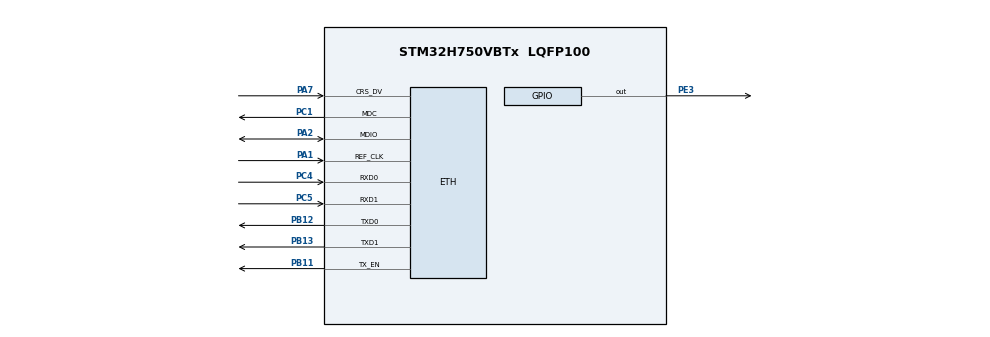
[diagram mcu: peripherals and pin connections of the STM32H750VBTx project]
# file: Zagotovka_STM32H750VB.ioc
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CORTEX_M7.AccessPermission-Cortex_Memory_Protection_Unit_Region0_Settings=MPU_REGION_FULL_ACCESS
CORTEX_M7.AccessPermission-Cortex_Memory_Protection_Unit_Region1_Settings=MPU_REGION_FULL_ACCESS
CORTEX_M7.AccessPermission-Cortex_Memory_Protection_Unit_Region2_Settings=MPU_REGION_FULL_ACCESS
CORTEX_M7.AccessPermission-Cortex_Memory_Protection_Unit_Region3_Settings=MPU_REGION_FULL_ACCESS
CORTEX_M7.BaseAddress-Cortex_Memory_Protection_Unit_Region0_Settings=0x30000000
CORTEX_M7.BaseAddress-Cortex_Memory_Protection_Unit_Region1_Settings=0x30000000
CORTEX_M7.BaseAddress-Cortex_Memory_Protection_Unit_Region2_Settings=0x90000000
CORTEX_M7.BaseAddress-Cortex_Memory_Protection_Unit_Region3_Settings=0x90000000
CORTEX_M7.CPU_DCache=Enabled
CORTEX_M7.CPU_ICache=Enabled
CORTEX_M7.DisableExec-Cortex_Memory_Protection_Unit_Region0_Settings=MPU_INSTRUCTION_ACCESS_DISABLE
CORTEX_M7.DisableExec-Cortex_Memory_Protection_Unit_Region1_Settings=MPU_INSTRUCTION_ACCESS_DISABLE
CORTEX_M7.DisableExec-Cortex_Memory_Protection_Unit_Region2_Settings=MPU_INSTRUCTION_ACCESS_DISABLE
CORTEX_M7.Enable-Cortex_Memory_Protection_Unit_Region0_Settings=MPU_REGION_ENABLE
CORTEX_M7.Enable-Cortex_Memory_Protection_Unit_Region1_Settings=MPU_REGION_ENABLE
CORTEX_M7.Enable-Cortex_Memory_Protection_Unit_Region2_Settings=MPU_REGION_ENABLE
CORTEX_M7.Enable-Cortex_Memory_Protection_Unit_Region3_Settings=MPU_REGION_ENABLE
CORTEX_M7.IsBufferable-Cortex_Memory_Protection_Unit_Region1_Settings=MPU_ACCESS_BUFFERABLE
CORTEX_M7.IsBufferable-Cortex_Memory_Protection_Unit_Region2_Settings=MPU_ACCESS_BUFFERABLE
CORTEX_M7.IsBufferable-Cortex_Memory_Protection_Unit_Region3_Settings=MPU_ACCESS_BUFFERABLE
CORTEX_M7.IsCacheable-Cortex_Memory_Protection_Unit_Region2_Settings=MPU_ACCESS_CACHEABLE
CORTEX_M7.IsCacheable-Cortex_Memory_Protection_Unit_Region3_Settings=MPU_ACCESS_CACHEABLE
CORTEX_M7.IsShareable-Cortex_Memory_Protection_Unit_Region1_Settings=MPU_ACCESS_SHAREABLE
CORTEX_M7.MPU_Control=MPU_PRIVILEGED_DEFAULT
CORTEX_M7.Size-Cortex_Memory_Protection_Unit_Region0_Settings=MPU_REGION_SIZE_32KB
CORTEX_M7.Size-Cortex_Memory_Protection_Unit_Region1_Settings=MPU_REGION_SIZE_256B
CORTEX_M7.Size-Cortex_Memory_Protection_Unit_Region2_Settings=MPU_REGION_SIZE_8MB
CORTEX_M7.Size-Cortex_Memory_Protection_Unit_Region3_Settings=MPU_REGION_SIZE_1MB
CORTEX_M7.TypeExtField-Cortex_Memory_Protection_Unit_Region0_Settings=MPU_TEX_LEVEL1
ETH.MediaInterface=HAL_ETH_RMII_MODE
FREERTOS.Tasks01=defaultTask,0,5000,StartDefaultTask,Default,NULL,Static,defaultTaskBuffer,defaultTaskControlBlock;myTask02,1,128,StartTask02,Default,NULL,Static,myTask02Buffer,myTask02ControlBlock
FREERTOS.configTOTAL_HEAP_SIZE=50000
FREERTOS.configUSE_NEWLIB_REENTRANT=1
LWIP.BSP.number=1
LWIP.DEFAULT_THREAD_STACKSIZE=2000
LWIP.GATEWAY_ADDRESS=195.168.018.001
LWIP.IP_ADDRESS=192.168.018.115
LWIP.LWIP_DHCP=0
LWIP.LWIP_HTTPD=1
LWIP.LWIP_HTTPD_CGI=1
LWIP.LWIP_HTTPD_DYNAMIC_HEADERS=0
LWIP.LWIP_HTTPD_MAX_TAG_INSERT_LEN=1000
LWIP.LWIP_HTTPD_SSI=1
LWIP.LWIP_HTTPD_SSI_INCLUDE_TAG=0
LWIP.LWIP_HTTPD_SSI_MULTIPART=1
LWIP.LWIP_HTTPD_SUPPORT_POST=1
LWIP.LWIP_RAM_HEAP_POINTER=0x30004000
LWIP.MEMP_NUM_TCP_PCB=6
LWIP.MEMP_NUM_UDP_PCB=6
LWIP.MEM_SIZE=10*1024
LWIP.NETMASK_ADDRESS=255.255.255.000
LWIP.PBUF_POOL_BUFSIZE=592
LWIP.TCPIP_THREAD_STACKSIZE=3072
LWIP.Version=v2.1.2_Cube
LWIP0.BSP.STBoard=false
LWIP0.BSP.api=BSP_COMPONENT_DRIVER
LWIP0.BSP.component=LAN8742
LWIP0.BSP.instance=LAN8742
LWIP0.BSP.name=Driver_PHY
LWIP0.BSP.semaphore=S_LAN8742
LWIP0.BSP.solution=LAN8742
Mcu.Family=STM32H7
Mcu.Name=STM32H750VBTx
Mcu.Package=LQFP100
NVIC.ETH_IRQn=true\:5\:0\:false\:false\:true\:true\:true\:true\:true
NVIC.PriorityGroup=NVIC_PRIORITYGROUP_4
NVIC.TIM17_IRQn=true\:15\:0\:false\:false\:true\:false\:false\:true\:true
NVIC.TimeBase=TIM17_IRQn
NVIC.TimeBaseIP=TIM17
PA1.GPIO_Speed=GPIO_SPEED_FREQ_VERY_HIGH
PA1.Mode=RMII
PA1.Signal=ETH_REF_CLK
PA2.GPIO_Speed=GPIO_SPEED_FREQ_VERY_HIGH
PA2.Mode=RMII
PA2.Signal=ETH_MDIO
PA7.GPIO_Speed=GPIO_SPEED_FREQ_VERY_HIGH
PA7.Mode=RMII
PA7.Signal=ETH_CRS_DV
PB11.GPIO_Speed=GPIO_SPEED_FREQ_VERY_HIGH
PB11.Mode=RMII
PB11.Signal=ETH_TX_EN
PB12.GPIO_Speed=GPIO_SPEED_FREQ_VERY_HIGH
PB12.Mode=RMII
PB12.Signal=ETH_TXD0
PB13.GPIO_Speed=GPIO_SPEED_FREQ_VERY_HIGH
PB13.Mode=RMII
PB13.Signal=ETH_TXD1
PC1.GPIO_Speed=GPIO_SPEED_FREQ_VERY_HIGH
PC1.Mode=RMII
PC1.Signal=ETH_MDC
PC4.GPIO_Speed=GPIO_SPEED_FREQ_VERY_HIGH
PC4.Mode=RMII
PC4.Signal=ETH_RXD0
PC5.GPIO_Speed=GPIO_SPEED_FREQ_VERY_HIGH
PC5.Mode=RMII
PC5.Signal=ETH_RXD1
PE3.Signal=GPIO_Output
PH0-OSC_IN\ (PH0).Mode=HSE-External-Oscillator
PH0-OSC_IN\ (PH0).Signal=RCC_OSC_IN
PH1-OSC_OUT\ (PH1).Mode=HSE-External-Oscillator
PH1-OSC_OUT\ (PH1).Signal=RCC_OSC_OUT
ProjectManager.HeapSize=0x200
ProjectManager.StackSize=0x400
ProjectManager.TargetToolchain=STM32CubeIDE
RCC.ADCFreq_Value=50390625
RCC.APB1Freq_Value=100000000
RCC.APB2Freq_Value=100000000
RCC.APB3Freq_Value=100000000
RCC.APB4Freq_Value=100000000
RCC.CortexFreq_Value=200000000
RCC.DIVM1=2
RCC.DIVN1=32
RCC.HCLKFreq_Value=100000000
RCC.HPRE=RCC_HCLK_DIV2
RCC.PLLSourceVirtual=RCC_PLLSOURCE_HSE
RCC.SYSCLKFreq_VALUE=200000000
RCC.SYSCLKSource=RCC_SYSCLKSOURCE_PLLCLK
RCC.USBFreq_Value=200000000
VP_FREERTOS_VS_CMSIS_V1.Mode=CMSIS_V1
VP_LWIP_VS_Enabled.Mode=Enabled
VP_SYS_VS_tim17.Mode=TIM17
board=custom

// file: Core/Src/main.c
/* USER CODE BEGIN Header */
/**
  ******************************************************************************
  * @file           : main.c
  * @brief          : Main program body
  ******************************************************************************
  * @attention
  *
  * Copyright (c) 2022 STMicroelectronics.
  * All rights reserved.
  *
  * This software is licensed under terms that can be found in the LICENSE file
  * in the root directory of this software component.
  * If no LICENSE file comes with this software, it is provided AS-IS.
  *
  ******************************************************************************
  */
/* USER CODE END Header */
#include "main.h"
#include "cmsis_os.h"
#include "lwip.h"

/* USER CODE BEGIN Includes */
#include "stdbool.h"

//#include "db.h"
#include <stdio.h>/* для printf */
#include "http_ssi.h"
#include "lwip/apps/httpd.h" // including httpd.h [- HTTPd #1 -]

/* USER CODE END Includes */

/* USER CODE BEGIN PTD */
//bool flag;
//unsigned long Tim;
/* USER CODE END PTD */

osThreadId defaultTaskHandle;
uint32_t defaultTaskBuffer[ 5000 ];
osStaticThreadDef_t defaultTaskControlBlock;
osThreadId myTask02Handle;
uint32_t myTask02Buffer[ 128 ];
osStaticThreadDef_t myTask02ControlBlock;

void SystemClock_Config(void);
static void MPU_Config(void);
static void MX_GPIO_Init(void);
void StartDefaultTask(void const * argument);
void StartTask02(void const * argument);

/* USER CODE BEGIN 0 */
extern struct netif gnetif;
/* USER CODE END 0 */

int main(void)
{

  /* MPU Configuration--------------------------------------------------------*/
  MPU_Config();

  /* Enable I-Cache---------------------------------------------------------*/
  SCB_EnableICache();

  /* Enable D-Cache---------------------------------------------------------*/
  SCB_EnableDCache();

  /* MCU Configuration--------------------------------------------------------*/

  /* Reset of all peripherals, Initializes the Flash interface and the Systick. */
  HAL_Init();

  /* Configure the system clock */
//  SystemClock_Config();

  /* Initialize all configured peripherals */
  MX_GPIO_Init();

  /* Create the thread(s) */
  /* definition and creation of defaultTask */
  osThreadStaticDef(defaultTask, StartDefaultTask, osPriorityNormal, 0, 5000, defaultTaskBuffer, &defaultTaskControlBlock);
  defaultTaskHandle = osThreadCreate(osThread(defaultTask), NULL);

  /* definition and creation of myTask02 */
  osThreadStaticDef(myTask02, StartTask02, osPriorityAboveNormal, 0, 128, myTask02Buffer, &myTask02ControlBlock);
  myTask02Handle = osThreadCreate(osThread(myTask02), NULL);

  /* Start scheduler */
  osKernelStart();

  /* We should never get here as control is now taken by the scheduler */
  /* Infinite loop */
  while (1)
  {

  }
}

void SystemClock_Config(void)
{
  RCC_OscInitTypeDef RCC_OscInitStruct = {0};
  RCC_ClkInitTypeDef RCC_ClkInitStruct = {0};

  /** Supply configuration update enable
  */
  HAL_PWREx_ConfigSupply(PWR_LDO_SUPPLY);

  /** Configure the main internal regulator output voltage
  */
  __HAL_PWR_VOLTAGESCALING_CONFIG(PWR_REGULATOR_VOLTAGE_SCALE3);

  while(!__HAL_PWR_GET_FLAG(PWR_FLAG_VOSRDY)) {}

  /** Initializes the RCC Oscillators according to the specified parameters
  * in the RCC_OscInitTypeDef structure.
  */
  RCC_OscInitStruct.OscillatorType = RCC_OSCILLATORTYPE_HSE;
  RCC_OscInitStruct.HSEState = RCC_HSE_ON;
  RCC_OscInitStruct.PLL.PLLState = RCC_PLL_ON;
  RCC_OscInitStruct.PLL.PLLSource = RCC_PLLSOURCE_HSE;
  RCC_OscInitStruct.PLL.PLLM = 2;
  RCC_OscInitStruct.PLL.PLLN = 32;
  RCC_OscInitStruct.PLL.PLLP = 2;
  RCC_OscInitStruct.PLL.PLLQ = 2;
  RCC_OscInitStruct.PLL.PLLR = 2;
  RCC_OscInitStruct.PLL.PLLRGE = RCC_PLL1VCIRANGE_3;
  RCC_OscInitStruct.PLL.PLLVCOSEL = RCC_PLL1VCOWIDE;
  RCC_OscInitStruct.PLL.PLLFRACN = 0;
  if (HAL_RCC_OscConfig(&RCC_OscInitStruct) != HAL_OK)
  {
    Error_Handler();
  }

  /** Initializes the CPU, AHB and APB buses clocks
  */
  RCC_ClkInitStruct.ClockType = RCC_CLOCKTYPE_HCLK|RCC_CLOCKTYPE_SYSCLK
                              |RCC_CLOCKTYPE_PCLK1|RCC_CLOCKTYPE_PCLK2
                              |RCC_CLOCKTYPE_D3PCLK1|RCC_CLOCKTYPE_D1PCLK1;
  RCC_ClkInitStruct.SYSCLKSource = RCC_SYSCLKSOURCE_PLLCLK;
  RCC_ClkInitStruct.SYSCLKDivider = RCC_SYSCLK_DIV1;
  RCC_ClkInitStruct.AHBCLKDivider = RCC_HCLK_DIV2;
  RCC_ClkInitStruct.APB3CLKDivider = RCC_APB3_DIV1;
  RCC_ClkInitStruct.APB1CLKDivider = RCC_APB1_DIV1;
  RCC_ClkInitStruct.APB2CLKDivider = RCC_APB2_DIV1;
  RCC_ClkInitStruct.APB4CLKDivider = RCC_APB4_DIV1;

  if (HAL_RCC_ClockConfig(&RCC_ClkInitStruct, FLASH_LATENCY_2) != HAL_OK)
  {
    Error_Handler();
  }
}

static void MX_GPIO_Init(void)
{
  GPIO_InitTypeDef GPIO_InitStruct = {0};

  /* GPIO Ports Clock Enable */
  __HAL_RCC_GPIOE_CLK_ENABLE();
  __HAL_RCC_GPIOH_CLK_ENABLE();
  __HAL_RCC_GPIOC_CLK_ENABLE();
  __HAL_RCC_GPIOA_CLK_ENABLE();
  __HAL_RCC_GPIOB_CLK_ENABLE();

  /*Configure GPIO pin Output Level */
  HAL_GPIO_WritePin(GPIOE, GPIO_PIN_3, GPIO_PIN_RESET);

  /*Configure GPIO pin : PE3 */
  GPIO_InitStruct.Pin = GPIO_PIN_3;
  GPIO_InitStruct.Mode = GPIO_MODE_OUTPUT_PP;
  GPIO_InitStruct.Pull = GPIO_NOPULL;
  GPIO_InitStruct.Speed = GPIO_SPEED_FREQ_LOW;
  HAL_GPIO_Init(GPIOE, &GPIO_InitStruct);

}

void StartDefaultTask(void const * argument)
{
  /* init code for LWIP */
  MX_LWIP_Init();
  /* USER CODE BEGIN 5 */
  http_server_init();
  /* Infinite loop */
  for(;;)
  {
    //osDelay(1);
  }
  /* USER CODE END 5 */
}

void StartTask02(void const * argument)
{
  /* USER CODE BEGIN StartTask02 */
  /* Infinite loop */
  for(;;)
  {
	  HAL_GPIO_TogglePin(GPIOE, GPIO_PIN_3);
	osDelay(500);
  }
  /* USER CODE END StartTask02 */
}

/* MPU Configuration */

void MPU_Config(void)
{
  MPU_Region_InitTypeDef MPU_InitStruct = {0};

  /* Disables the MPU */
  HAL_MPU_Disable();

  /** Initializes and configures the Region and the memory to be protected
  */
  MPU_InitStruct.Enable = MPU_REGION_ENABLE;
  MPU_InitStruct.Number = MPU_REGION_NUMBER0;
  MPU_InitStruct.BaseAddress = 0x30000000;
  MPU_InitStruct.Size = MPU_REGION_SIZE_32KB;
  MPU_InitStruct.SubRegionDisable = 0x0;
  MPU_InitStruct.TypeExtField = MPU_TEX_LEVEL1;
  MPU_InitStruct.AccessPermission = MPU_REGION_FULL_ACCESS;
  MPU_InitStruct.DisableExec = MPU_INSTRUCTION_ACCESS_DISABLE;
  MPU_InitStruct.IsShareable = MPU_ACCESS_NOT_SHAREABLE;
  MPU_InitStruct.IsCacheable = MPU_ACCESS_NOT_CACHEABLE;
  MPU_InitStruct.IsBufferable = MPU_ACCESS_NOT_BUFFERABLE;

  HAL_MPU_ConfigRegion(&MPU_InitStruct);

  /** Initializes and configures the Region and the memory to be protected
  */
  MPU_InitStruct.Number = MPU_REGION_NUMBER1;
  MPU_InitStruct.Size = MPU_REGION_SIZE_256B;
  MPU_InitStruct.TypeExtField = MPU_TEX_LEVEL0;
  MPU_InitStruct.IsShareable = MPU_ACCESS_SHAREABLE;
  MPU_InitStruct.IsBufferable = MPU_ACCESS_BUFFERABLE;

  HAL_MPU_ConfigRegion(&MPU_InitStruct);

  /** Initializes and configures the Region and the memory to be protected
  */
  MPU_InitStruct.Number = MPU_REGION_NUMBER2;
  MPU_InitStruct.BaseAddress = 0x90000000;
  MPU_InitStruct.Size = MPU_REGION_SIZE_8MB;
  MPU_InitStruct.IsShareable = MPU_ACCESS_NOT_SHAREABLE;
  MPU_InitStruct.IsCacheable = MPU_ACCESS_CACHEABLE;

  HAL_MPU_ConfigRegion(&MPU_InitStruct);

  /** Initializes and configures the Region and the memory to be protected
  */
  MPU_InitStruct.Number = MPU_REGION_NUMBER3;
  MPU_InitStruct.Size = MPU_REGION_SIZE_1MB;
  MPU_InitStruct.DisableExec = MPU_INSTRUCTION_ACCESS_ENABLE;

  HAL_MPU_ConfigRegion(&MPU_InitStruct);
  /* Enables the MPU */
  HAL_MPU_Enable(MPU_PRIVILEGED_DEFAULT);

}

void HAL_TIM_PeriodElapsedCallback(TIM_HandleTypeDef *htim)
{
  if (htim->Instance == TIM17) {
    HAL_IncTick();
  }
}

void Error_Handler(void)
{
  __disable_irq();
  while (1)
  {
  }
}
